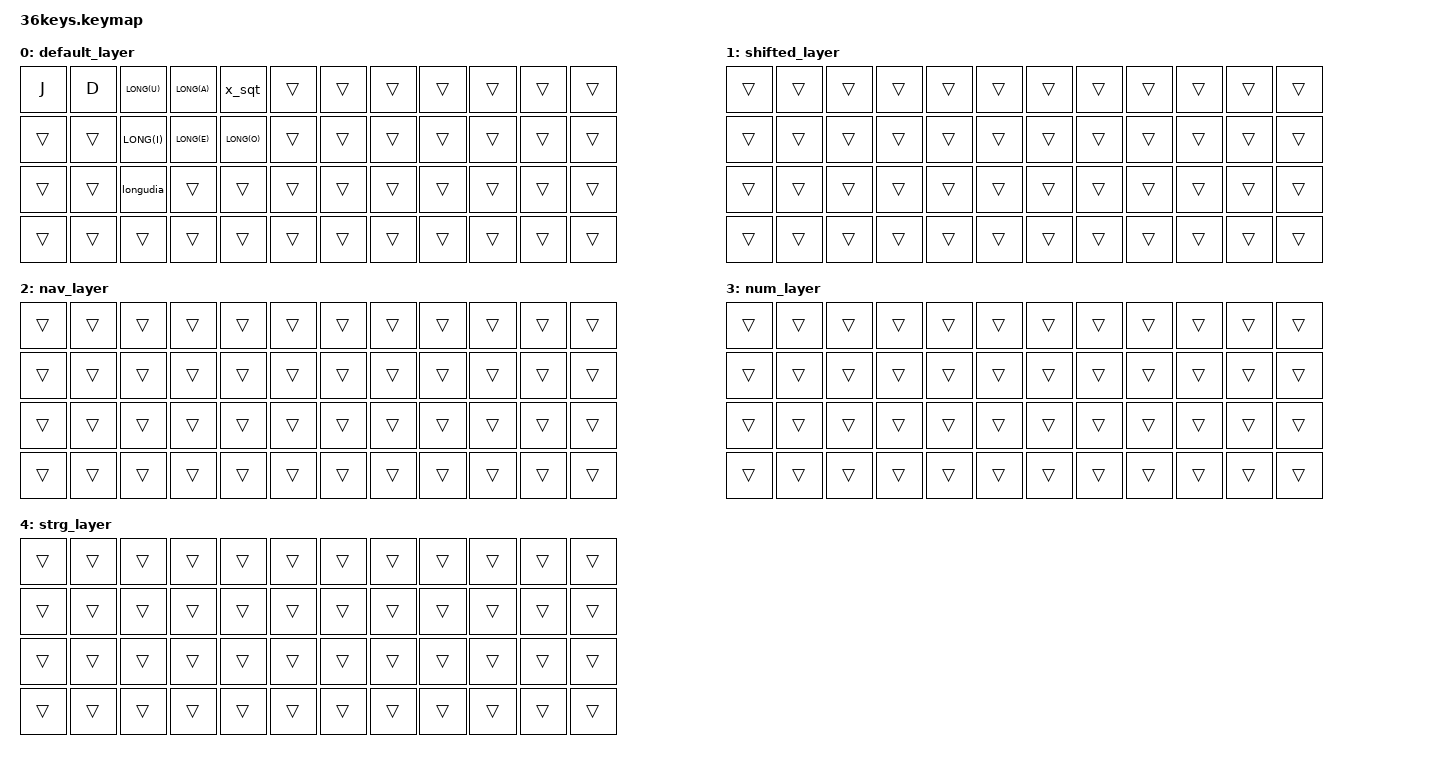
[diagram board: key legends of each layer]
#include "functions.dtsi"
#include <behaviors.dtsi>
#include "keymap_german.h"

#include <dt-bindings/zmk/keys.h>
#include <dt-bindings/zmk/bt.h>
#include "helper.h"
//#include "../zmk-nodefree-config/keypos_def/keypos_48keys.h"
//#include "../zmk-nodefree-config/international_chars/german.dtsi"

#define ___ &trans
#define XXX &none

#define DEF         0
#define SHIF        1
#define NAV         2
#define NUM         3
#define STRG        4

//#include "combos.dtsi" //muss nach den layerdefs sein

#define LONG(keycode) &long keycode keycode

/ {
    behaviors {
        long: long {
            compatible = "zmk,behavior-hold-tap";
            //label = "long";
            #binding-cells = <2>;
            flavor = "tap-preferred";
            tapping-term-ms = <200>;
            bindings = <&kp>, <&m_elongate>;
        };

        longudia: longudia {
            compatible = "zmk,behavior-hold-tap";
            //label = "longudia";
            #binding-cells = <2>;
            flavor = "tap-preferred";
            tapping-term-ms = <200>;
            bindings = <&kp DE_UDIA>, <&m_longudia>;
        };

        x_sqt: x_sqt {
            compatible = "zmk,behavior-hold-tap";
            //label = "x_sqt";
            #binding-cells = <2>;
            flavor = "tap-preferred";
            tapping-term-ms = <200>;
            bindings = <&kp X>, <&kp DE_SQT>;
        };
    };

/ {
    macros {
        m_elongate: m_elongate {
            //label = "m_elongate";
            compatible = "zmk,behavior-macro";
            #binding-cells = <0>;
            bindings
                = <&macro_tap &kp DE_ACUT> 
                , <&kp>
                ;
        };
        
        m_longudia: m_longudia {
            //label = "m_longudia";
            compatible = "zmk,behavior-macro";
            #binding-cells = <0>;
            bindings
                = <&macro_press &kp LALT> 
                , <&macro_tap &kp KP_N0 &kp KP_N3 &kp KP_N6 &kp KP_N9 >
                , <&macro_release &kp LALT> 
                ;
        };
    };
};

ZMK_LAYER(default_layer,
 &kp J &kp D LONG(U) LONG(A) &x_sqt ___ ___ ___ ___ ___ ___ ___
 ___ ___ LONG(I) LONG(E) LONG(O) ___ ___ ___ ___ ___ ___ ___
  ___ ___ &longudia ___ ___ ___ ___ ___ ___ ___ ___ ___
   ___ ___ ___ ___ ___ ___ ___ ___ ___ ___ ___ ___
)

ZMK_LAYER(shifted_layer,
 ___ ___ ___ ___ ___ ___ ___ ___ ___ ___ ___ ___
  ___ ___ ___ ___ ___ ___ ___ ___ ___ ___ ___ ___
   ___ ___ ___ ___ ___ ___ ___ ___ ___ ___ ___ ___
    ___ ___ ___ ___ ___ ___ ___ ___ ___ ___ ___ ___
)

ZMK_LAYER(nav_layer,
 ___ ___ ___ ___ ___ ___ ___ ___ ___ ___ ___ ___
  ___ ___ ___ ___ ___ ___ ___ ___ ___ ___ ___ ___
   ___ ___ ___ ___ ___ ___ ___ ___ ___ ___ ___ ___
    ___ ___ ___ ___ ___ ___ ___ ___ ___ ___ ___ ___
    )

ZMK_LAYER(num_layer,
 ___ ___ ___ ___ ___ ___ ___ ___ ___ ___ ___ ___
  ___ ___ ___ ___ ___ ___ ___ ___ ___ ___ ___ ___
   ___ ___ ___ ___ ___ ___ ___ ___ ___ ___ ___ ___
    ___ ___ ___ ___ ___ ___ ___ ___ ___ ___ ___ ___
    )

ZMK_LAYER(strg_layer,
 ___ ___ ___ ___ ___ ___ ___ ___ ___ ___ ___ ___
  ___ ___ ___ ___ ___ ___ ___ ___ ___ ___ ___ ___
   ___ ___ ___ ___ ___ ___ ___ ___ ___ ___ ___ ___
    ___ ___ ___ ___ ___ ___ ___ ___ ___ ___ ___ ___)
